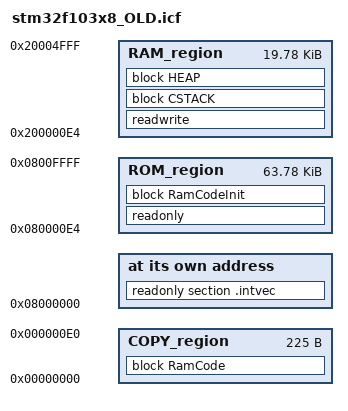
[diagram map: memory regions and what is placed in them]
/*###ICF### Section handled by ICF editor, don't touch! ****/
/*-Editor annotation file-*/
/* IcfEditorFile="$TOOLKIT_DIR$\config\ide\IcfEditor\cortex_v1_0.xml" */
/*-Specials-*/
define symbol __ICFEDIT_intvec_start__ = 0x08000000;
/*-Memory Regions-*/
define symbol __ICFEDIT_region_ROM_start__ = 0x080000E4;
define symbol __ICFEDIT_region_ROM_end__   = 0x0800FFFF;
define symbol __ICFEDIT_region_RAM_start__ = 0x200000E4;
define symbol __ICFEDIT_region_RAM_end__   = 0x20004FFF;
/*-Sizes-*/
define symbol __ICFEDIT_size_cstack__ = 0x800;
define symbol __ICFEDIT_size_heap__   = 0x800;
/**** End of ICF editor section. ###ICF###*/

define memory mem with size = 4G;
define region ROM_region   = mem:[from __ICFEDIT_region_ROM_start__   to __ICFEDIT_region_ROM_end__];
define region RAM_region   = mem:[from __ICFEDIT_region_RAM_start__   to __ICFEDIT_region_RAM_end__];

define block CSTACK    with alignment = 8, size = __ICFEDIT_size_cstack__   { };
define block HEAP      with alignment = 8, size = __ICFEDIT_size_heap__     { };

initialize by copy { readwrite };
do not initialize  { section .noinit };

place at address mem:__ICFEDIT_intvec_start__ { readonly section .intvec };

place in ROM_region   { readonly };
place in RAM_region   { readwrite,
                        block CSTACK, block HEAP };
						
define symbol _region_COPY_start__   = 0x00;
define symbol _region_COPY_end__     = 0xE0;
define region COPY_region = mem:[from _region_COPY_start__ to _region_COPY_end__];

initialize by copy { section .intvec_RAM };
define block RamCode { section .intvec_RAM };
define block RamCodeInit { section .intvec_RAM_init };
place in ROM_region { block RamCodeInit };
place in COPY_region { block RamCode };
